# MEC1727N_B0_SZ register map
Vendor: Microchip Technology; Series: MEC172x; File version: 0
CPU: CM4 r1p0, little endian, MPU, FPU, 3 interrupt priority bits, 172 interrupts
Registers are 32-bit, read-write, reset 0x0 unless marked. A register's access mark holds for its fields unless they carry their own. Offsets are from the block's base; [hi:lo] are bit positions.

## POWERGUARD_0 — This block monitors PowerGuard output signals (or locked rotor signals) from various types of fans, and determines their speed.
Base 0x40003000; register names take the prefix POWERGUARD_
Same registers: POWERGUARD_1 0x40003080
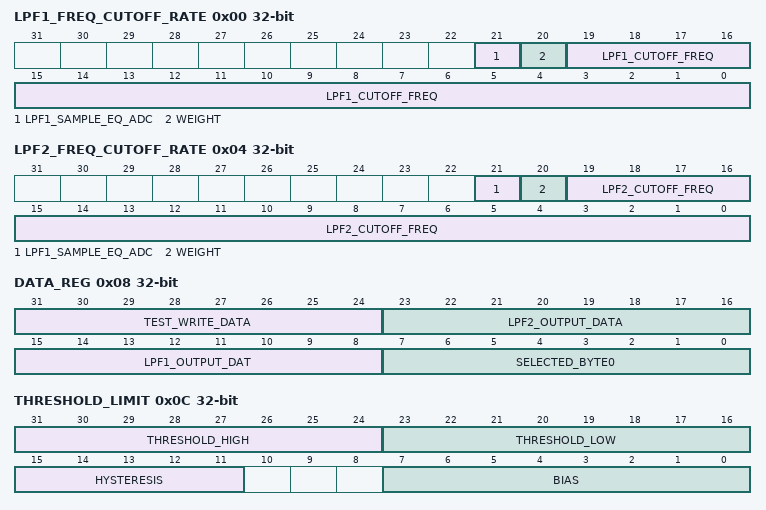
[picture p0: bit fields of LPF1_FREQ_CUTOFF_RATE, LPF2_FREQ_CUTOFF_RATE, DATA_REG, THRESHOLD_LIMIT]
0x00 LPF1_FREQ_CUTOFF_RATE — LPF1 Frequency Cut-off Rate Register
  [21] LPF1_SAMPLE_EQ_ADC — FILTER_ENABLE This bit controls the LPF1 sampling rate.
  [20] WEIGHT — This bit controls the weight parameter W in the First Order Average Equation and the weight parameter W2 in the Second Order Average Equation for Linear Predictive Filter 1.
  [19:0] LPF1_CUTOFF_FREQ — The cutoff frequency for the Linear Predictive Filter 1.
0x04 LPF2_FREQ_CUTOFF_RATE — LPF2 Frequency Cut-off Rate Register
  [21] LPF1_SAMPLE_EQ_ADC — FILTER_ENABLE This bit controls the LPF1 sampling rate.
  [20] WEIGHT — This bit controls the weight parameter W in the First Order Average Equation and the weight parameter W2 in the Second Order Average Equation for Linear Predictive Filter 1.
  [19:0] LPF2_CUTOFF_FREQ — The cutoff frequency for the Linear Predictive Filter 2.
0x08 DATA_REG — Data Register
  [31:24] TEST_WRITE_DATA — When the TEST_DATA_MUX_SELECT bit in the Control And Status Register is a 1, writes to this register are used as the ADC sample data.
  [23:16] LPF2_OUTPUT_DATA — Data output of 2nd Order LPF.
  [15:8] LPF1_OUTPUT_DAT — Data output of 1st Order LPF.
  [7:0] SELECTED_BYTE0 — The contents of this read-only field is controlled by the value written into the DATA_MUX_SELECT field in the Control And Status Register.
0x0C THRESHOLD_LIMIT
  [31:24] THRESHOLD_HIGH — This field contains the base value for setting the comparison threshold for the high-side comparator.
  [23:16] THRESHOLD_LOW — This field contains the base value for setting the comparison threshold for the low-side comparator.
  [15:11] HYSTERESIS — The contents of this field is added or subtracted both comparator thresholds, based on the hysteresis settings for the comparators.
  [7:0] BIAS — The contents of this field are added to both THRESHOLD_HIGH and THRESHOLD_LOW when generating the comparison thresholds for the high-side and low-side comparators, respectively.
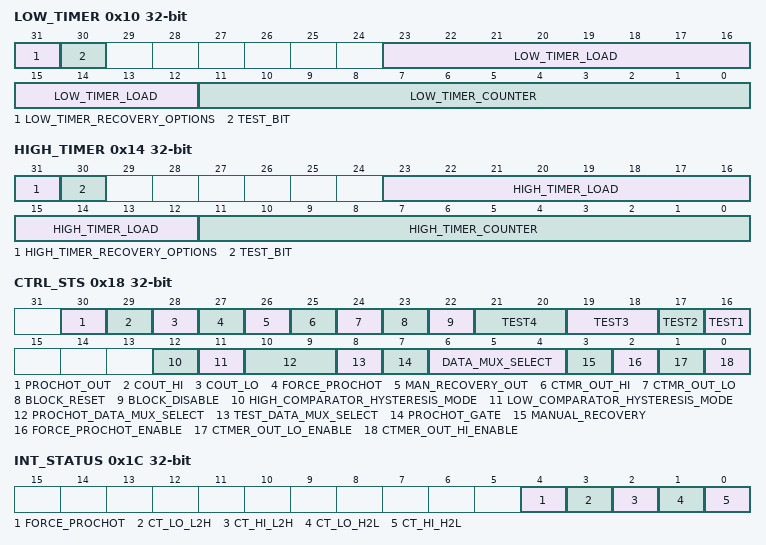
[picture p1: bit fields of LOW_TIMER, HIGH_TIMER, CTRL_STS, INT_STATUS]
0x10 LOW_TIMER
  [31] LOW_TIMER_RECOVERY_OPTIONS — Recovery mode for the low-side timer.
  [30] TEST_BIT — All writes to this register should clear this test bit to 0.
  [23:12] LOW_TIMER_LOAD — The value written into this field is the Load Count value for the LOW_TIMER_COUNTER.
  [11:0] LOW_TIMER_COUNTER — Reads of this field provides the current count of the low-side timer.
0x14 HIGH_TIMER
  [31] HIGH_TIMER_RECOVERY_OPTIONS — Recovery mode for the high-side timer.
  [30] TEST_BIT — All writes to this register should clear this test bit to 0.
  [23:12] HIGH_TIMER_LOAD — The value written into this field is the Load Count value for the HIGH_TIMER_COUNTER.
  [11:0] HIGH_TIMER_COUNTER — Reads of this field provides the current count of the high-side timer.
0x18 CTRL_STS — Control and Status Register.
  [30] PROCHOT_OUT — Current output of the ORing Logic.
  [29] COUT_HI — Current output of the high-side comparator.
  [28] COUT_LO — Current output of the low-side comparator.
  [27] FORCE_PROCHOT — Inverted copy of the current state of the input signal FORCE_PROCHOT# from the PROCHOT PWM.
  [26] MAN_RECOVERY_OUT — If both the high-side timer and the low-side timer are configured for Manual Recovery Mode, this bit reports the status of the timer contribution to the ORing Logic.
  [25] CTMR_OUT_HI — Status bit of the high-side timer.
  [24] CTMR_OUT_LO — Status bit of the low-side timer.
  [23] BLOCK_RESET — When this bit is set to '1b' the entire block is reset.
  [22] BLOCK_DISABLE — When this bit is set to '1b' the PowerGuard block is disabled and placed in a low power state.
  [21:20] TEST4 — All writes to this register should clear this test bit to 0.
  [19:18] TEST3 — All writes to this register should clear this test bit to 0.
  [17] TEST2 — All writes to this register should clear this test bit to 0.
  [16] TEST1 — All writes to this register should clear this test bit to 0.
  [12] HIGH_COMPARATOR_HYSTERESIS_MODE — This bit selects Hysteresis Mode for the high-side comparator.
  [11] LOW_COMPARATOR_HYSTERESIS_MODE — This bit selects Hysteresis Mode for the low-side comparator.
  [10:9] PROCHOT_DATA_MUX_SELECT — This field controls the source of the Prochot Data Mux.
  [8] TEST_DATA_MUX_SELECT — This bit controls the source of the ADC sample data to the Second Order LPF.
  [7] PROCHOT_GATE — This bit controls the effect of the VCI_OVRD_IN pin on the PROCHOT_IO# Output.
  [6:4] DATA_MUX_SELECT — The field controls the read data accessible of the SELECTED_- BYTE0 field of the Data Register.
  [3] MANUAL_RECOVERY — This bit is set to '1b' if either high-side timer or the low-side timer is configured for Manual Recovery Mode and the timer times out and asserts.
  [2] FORCE_PROCHOT_ENABLE — FORCE_PROCHOT Enable bit
  [1] CTMER_OUT_LO_ENABLE — The low-side timer output enable bit.
  [0] CTMER_OUT_HI_ENABLE — The high-side timer output enable bit.
0x1C INT_STATUS — PowerGuard Interrupt Status Register
  [4] FORCE_PROCHOT — This bit is set to '1b' if the FORCE_PROCHOT# input from the PROCHOT PWM is low (asserted). (R/WC)
  [3] CT_LO_L2H — This bit is set to 1b when the CTMR_OUT_LO in the Control And Status Register transitions from '0b' to '1b'. (R/WC)
  [2] CT_HI_L2H — This bit is set to 1b when the CTMR_OUT_HI in the Control And Status Register transitions from '0b' to '1b'. (R/WC)
  [1] CT_LO_H2L — This bit is set to 1b when the CTMR_OUT_LO in the Control And Status Register transitions from '1b' to '0b'. (R/WC)
  [0] CT_HI_H2L — This bit is set to 1b when the CTMR_OUT_HI in the Control And Status Register transitions from '1b' to '0b'. (R/WC)
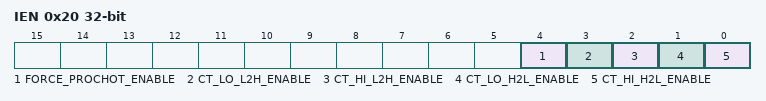
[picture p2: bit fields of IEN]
0x20 IEN — PowerGuard Interrupt Enable Register
  [4] FORCE_PROCHOT_ENABLE — This bit is used to enable/disable the FORCE_PROCHOT# interrupt.
  [3] CT_LO_L2H_ENABLE — This bit is used to enable/disable the CTMR_OUT_LO interrupt.
  [2] CT_HI_L2H_ENABLE — This bit is used to enable/disable the CTMR_OUT_HI interrupt.
  [1] CT_LO_H2L_ENABLE — This bit is used to enable/disable the CTMR_OUT_LO interrupt.
  [0] CT_HI_H2L_ENABLE — This bit is used to enable/disable the CTMR_OUT_HI interrupt.
